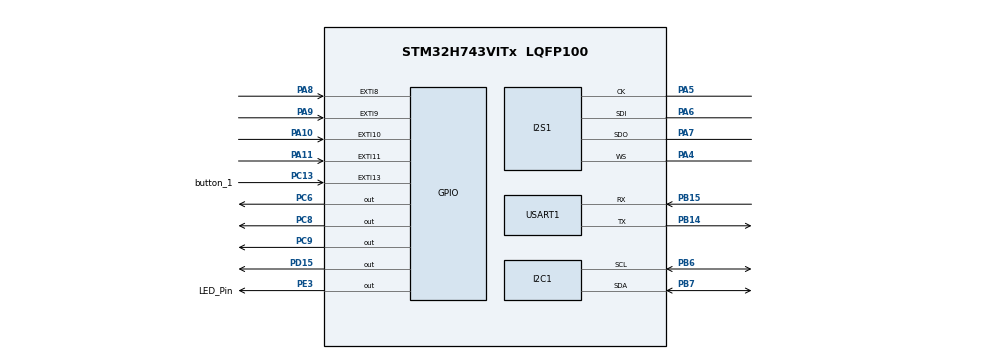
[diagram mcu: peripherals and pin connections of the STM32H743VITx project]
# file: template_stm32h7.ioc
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CORTEX_M7.CPU_DCache=Enabled
CORTEX_M7.CPU_ICache=Enabled
CORTEX_M7.default_mode_Activation=1
Dma.Request0=SPI1_RX
Dma.SPI1_RX.0.Direction=DMA_PERIPH_TO_MEMORY
Dma.SPI1_RX.0.EventEnable=DISABLE
Dma.SPI1_RX.0.FIFOMode=DMA_FIFOMODE_DISABLE
Dma.SPI1_RX.0.Instance=DMA1_Stream0
Dma.SPI1_RX.0.MemDataAlignment=DMA_MDATAALIGN_WORD
Dma.SPI1_RX.0.MemInc=DMA_MINC_ENABLE
Dma.SPI1_RX.0.Mode=DMA_CIRCULAR
Dma.SPI1_RX.0.PeriphDataAlignment=DMA_PDATAALIGN_WORD
Dma.SPI1_RX.0.PeriphInc=DMA_PINC_DISABLE
Dma.SPI1_RX.0.Polarity=HAL_DMAMUX_REQ_GEN_RISING
Dma.SPI1_RX.0.Priority=DMA_PRIORITY_LOW
Dma.SPI1_RX.0.RequestNumber=1
Dma.SPI1_RX.0.SignalID=NONE
Dma.SPI1_RX.0.SyncEnable=DISABLE
Dma.SPI1_RX.0.SyncPolarity=HAL_DMAMUX_SYNC_NO_EVENT
Dma.SPI1_RX.0.SyncRequestNumber=1
Dma.SPI1_RX.0.SyncSignalID=NONE
I2C1.Timing=0x307075B1
I2S1.AudioFreq=I2S_AUDIOFREQ_16K
I2S1.Data24BitAlignment=I2S_DATA_24BIT_ALIGNMENT_LEFT
I2S1.DataFormat=I2S_DATAFORMAT_24B
I2S1.ErrorAudioFreq=0.15 %
I2S1.Instance=SPI$Index
I2S1.RealAudioFreq=16.025 KHz
I2S1.WSInversion=I2S_WS_INVERSION_ENABLE
Mcu.Family=STM32H7
Mcu.Name=STM32H743VITx
Mcu.Package=LQFP100
NVIC.DMA1_Stream0_IRQn=true\:0\:0\:false\:false\:true\:false\:true\:true
NVIC.EXTI15_10_IRQn=true\:0\:0\:false\:false\:true\:true\:true\:true
NVIC.EXTI9_5_IRQn=true\:0\:0\:false\:false\:true\:true\:true\:true
NVIC.PriorityGroup=NVIC_PRIORITYGROUP_4
NVIC.TIM6_DAC_IRQn=true\:15\:0\:false\:false\:true\:false\:true\:true
NVIC.TimeBase=TIM6_DAC_IRQn
NVIC.TimeBaseIP=TIM6
PA10.GPIO_ModeDefaultEXTI=GPIO_MODE_IT_FALLING
PA10.GPIO_PuPd=GPIO_PULLUP
PA10.Signal=GPXTI10
PA11.GPIO_ModeDefaultEXTI=GPIO_MODE_IT_FALLING
PA11.GPIO_PuPd=GPIO_PULLUP
PA11.Signal=GPXTI11
PA13\ (JTMS/SWDIO).Mode=Serial_Wire
PA13\ (JTMS/SWDIO).Signal=DEBUG_JTMS-SWDIO
PA14\ (JTCK/SWCLK).Mode=Serial_Wire
PA14\ (JTCK/SWCLK).Signal=DEBUG_JTCK-SWCLK
PA4.GPIO_Speed=GPIO_SPEED_FREQ_VERY_HIGH
PA4.Mode=Full_Duplex_Master
PA4.Signal=I2S1_WS
PA5.GPIO_Speed=GPIO_SPEED_FREQ_VERY_HIGH
PA5.Mode=Full_Duplex_Master
PA5.Signal=I2S1_CK
PA6.GPIO_PuPd=GPIO_PULLDOWN
PA6.GPIO_Speed=GPIO_SPEED_FREQ_VERY_HIGH
PA6.Mode=Full_Duplex_Master
PA6.Signal=I2S1_SDI
PA7.Mode=Full_Duplex_Master
PA7.Signal=I2S1_SDO
PA8.GPIO_ModeDefaultEXTI=GPIO_MODE_IT_FALLING
PA8.GPIO_PuPd=GPIO_PULLUP
PA8.Signal=GPXTI8
PA9.GPIO_ModeDefaultEXTI=GPIO_MODE_IT_FALLING
PA9.GPIO_PuPd=GPIO_PULLUP
PA9.Signal=GPXTI9
PB14.Mode=Asynchronous
PB14.Signal=USART1_TX
PB15.Mode=Asynchronous
PB15.Signal=USART1_RX
PB6.Mode=I2C
PB6.Signal=I2C1_SCL
PB7.Mode=I2C
PB7.Signal=I2C1_SDA
PC13.GPIO_Label=button_1
PC13.GPIO_PuPd=GPIO_PULLDOWN
PC13.Signal=GPXTI13
PC14-OSC32_IN\ (OSC32_IN).Mode=LSE-External-Oscillator
PC14-OSC32_IN\ (OSC32_IN).Signal=RCC_OSC32_IN
PC15-OSC32_OUT\ (OSC32_OUT).Mode=LSE-External-Oscillator
PC15-OSC32_OUT\ (OSC32_OUT).Signal=RCC_OSC32_OUT
PC6.GPIO_Speed=GPIO_SPEED_FREQ_VERY_HIGH
PC6.Signal=GPIO_Output
PC8.GPIO_Speed=GPIO_SPEED_FREQ_VERY_HIGH
PC8.Signal=GPIO_Output
PC9.GPIO_Speed=GPIO_SPEED_FREQ_VERY_HIGH
PC9.Signal=GPIO_Output
PD15.GPIO_Speed=GPIO_SPEED_FREQ_VERY_HIGH
PD15.Signal=GPIO_Output
PE3.GPIO_Label=LED_Pin
PE3.GPIO_PuPd=GPIO_PULLUP
PE3.GPIO_Speed=GPIO_SPEED_FREQ_VERY_HIGH
PE3.Signal=GPIO_Output
PH0-OSC_IN\ (PH0).Mode=HSE-External-Oscillator
PH0-OSC_IN\ (PH0).Signal=RCC_OSC_IN
PH1-OSC_OUT\ (PH1).Mode=HSE-External-Oscillator
PH1-OSC_OUT\ (PH1).Signal=RCC_OSC_OUT
ProjectManager.HeapSize=0x800
ProjectManager.StackSize=0x800
ProjectManager.TargetToolchain=STM32CubeIDE
RCC.ADCFreq_Value=200000000
RCC.APB1CLKDivider=RCC_HCLK_DIV4
RCC.APB1Freq_Value=120000000
RCC.APB2CLKDivider=RCC_HCLK_DIV2
RCC.APB2Freq_Value=120000000
RCC.APB3Freq_Value=120000000
RCC.APB4Freq_Value=120000000
RCC.CortexFreq_Value=480000000
RCC.D1PPRE=RCC_APB3_DIV2
RCC.D2PPRE1=RCC_APB1_DIV2
RCC.D2PPRE2=RCC_APB2_DIV2
RCC.D3PPRE=RCC_APB4_DIV2
RCC.DIVM1=5
RCC.DIVM2=5
RCC.DIVM3=4
RCC.DIVN1=192
RCC.DIVN2=80
RCC.DIVN3=480
RCC.DIVQ1=20
RCC.DIVQ3=8
RCC.FLatency=FLASH_LATENCY_4
RCC.HCLKFreq_Value=240000000
RCC.HPRE=RCC_HCLK_DIV2
RCC.HSE_VALUE=25000000
RCC.PLL2FRACN=0
RCC.PLL3FRACN=0
RCC.PLLFRACN=0
RCC.PLLM=25
RCC.PLLMUL=RCC_PLL_MUL9
RCC.PLLN=432
RCC.PLLQ=9
RCC.PLLSourceVirtual=RCC_PLLSOURCE_HSE
RCC.PRESCALERUSB=RCC_USBCLKSOURCE_PLL_DIV1_5
RCC.PWR_Regulator_Voltage_Scale=PWR_REGULATOR_VOLTAGE_SCALE0
RCC.SPI123CLockSelection=RCC_SPI123CLKSOURCE_PLL2
RCC.SYSCLKFreq_VALUE=480000000
RCC.SYSCLKSource=RCC_SYSCLKSOURCE_PLLCLK
RCC.SYSCLKSourceVirtual=RCC_SYSCLKSOURCE_PLLCLK
RCC.USBFreq_Value=48000000
STMicroelectronics.X-CUBE-AI.10.0.0.ActivationBufferSizeList=143044
STMicroelectronics.X-CUBE-AI.10.0.0.ActivationBuffers=pool0
STMicroelectronics.X-CUBE-AI.10.0.0.ActivationNames=pool0
STMicroelectronics.X-CUBE-AI.10.0.0.ActivationSizes=AI_NETWORK_DATA_ACTIVATION_1_SIZE
STMicroelectronics.X-CUBE-AI.10.0.0.ApplicationCcDeviceJjApplication=Validation
STMicroelectronics.X-CUBE-AI.10.0.0.BSP.number=1
STMicroelectronics.X-CUBE-AI.10.0.0.HeapSize=0x800
STMicroelectronics.X-CUBE-AI.10.0.0.InternalRamActivationBufferMaxSize=AI_NETWORK_DATA_ACTIVATIONS_SIZE
STMicroelectronics.X-CUBE-AI.10.0.0.LatestDirectoryUsed-23a5d2a3259b84d5ab143782c94374b90ed32390b56418b2c5c6ee772b9fe1ea=C\:\\GitHub\\voiceprint_recognition\\models\\voiceprint_model
STMicroelectronics.X-CUBE-AI.10.0.0.MaximumNumberOfInputLayer=1
STMicroelectronics.X-CUBE-AI.10.0.0.MaximumNumberOfOutputLayer=1
STMicroelectronics.X-CUBE-AI.10.0.0.MaximumSizeOfInputLayer=1
STMicroelectronics.X-CUBE-AI.10.0.0.MaximumSizeOfOutputLayer=1
STMicroelectronics.X-CUBE-AI.10.0.0.ModelActualCompression-23a5d2a3259b84d5ab143782c94374b90ed32390b56418b2c5c6ee772b9fe1ea=0.0
STMicroelectronics.X-CUBE-AI.10.0.0.ModelCompression-23a5d2a3259b84d5ab143782c94374b90ed32390b56418b2c5c6ee772b9fe1ea=None
STMicroelectronics.X-CUBE-AI.10.0.0.ModelFlashOccupation-23a5d2a3259b84d5ab143782c94374b90ed32390b56418b2c5c6ee772b9fe1ea=298795
STMicroelectronics.X-CUBE-AI.10.0.0.ModelHashList=23a5d2a3259b84d5ab143782c94374b90ed32390b56418b2c5c6ee772b9fe1ea
STMicroelectronics.X-CUBE-AI.10.0.0.ModelKind-23a5d2a3259b84d5ab143782c94374b90ed32390b56418b2c5c6ee772b9fe1ea=TFLITE
STMicroelectronics.X-CUBE-AI.10.0.0.ModelMacc-23a5d2a3259b84d5ab143782c94374b90ed32390b56418b2c5c6ee772b9fe1ea=33718160
STMicroelectronics.X-CUBE-AI.10.0.0.ModelName-23a5d2a3259b84d5ab143782c94374b90ed32390b56418b2c5c6ee772b9fe1ea=network
STMicroelectronics.X-CUBE-AI.10.0.0.ModelNameList=network
STMicroelectronics.X-CUBE-AI.10.0.0.ModelRamOccupation-23a5d2a3259b84d5ab143782c94374b90ed32390b56418b2c5c6ee772b9fe1ea=143044
STMicroelectronics.X-CUBE-AI.10.0.0.ModelStructureFile-23a5d2a3259b84d5ab143782c94374b90ed32390b56418b2c5c6ee772b9fe1ea=C\:\\GitHub\\voiceprint_recognition\\models\\voiceprint_model\\voiceprint_model.tflite
STMicroelectronics.X-CUBE-AI.10.0.0.ModelType-23a5d2a3259b84d5ab143782c94374b90ed32390b56418b2c5c6ee772b9fe1ea=STM32Cube.AI MCU runtime
STMicroelectronics.X-CUBE-AI.10.0.0.ReadyForCodeGeneration=true
STMicroelectronics.X-CUBE-AI.10.0.0.StackSize=0x800
STMicroelectronics.X-CUBE-AI.10.0.0.WorkingBufferStartAddrList=0xFFFFFFFF
STMicroelectronics.X-CUBE-AI.10.0.0.XAaCUBEAaAICcArtificialOoIntelligenceJjCore=true
STMicroelectronics.X-CUBE-AI.10.0.0.copyWeightToRam=false
STMicroelectronics.X-CUBE-AI.10.0.0.copyWeightToRam-23a5d2a3259b84d5ab143782c94374b90ed32390b56418b2c5c6ee772b9fe1ea=false
STMicroelectronics.X-CUBE-AI.10.0.0.customLayerConfigEnabled=false
STMicroelectronics.X-CUBE-AI.10.0.0.customLayerConfigEnabled-23a5d2a3259b84d5ab143782c94374b90ed32390b56418b2c5c6ee772b9fe1ea=false
STMicroelectronics.X-CUBE-AI.10.0.0.noOnnxIoTranspose=false
STMicroelectronics.X-CUBE-AI.10.0.0.noOnnxIoTranspose-23a5d2a3259b84d5ab143782c94374b90ed32390b56418b2c5c6ee772b9fe1ea=false
STMicroelectronics.X-CUBE-AI.10.0.0.useInputAllocation=true
STMicroelectronics.X-CUBE-AI.10.0.0.useInputAllocation-23a5d2a3259b84d5ab143782c94374b90ed32390b56418b2c5c6ee772b9fe1ea=true
STMicroelectronics.X-CUBE-AI.10.0.0.useOutputAllocation=true
STMicroelectronics.X-CUBE-AI.10.0.0.useOutputAllocation-23a5d2a3259b84d5ab143782c94374b90ed32390b56418b2c5c6ee772b9fe1ea=true
STMicroelectronics.X-CUBE-AI.10.0.00.BSP.STBoard=false
STMicroelectronics.X-CUBE-AI.10.0.00.BSP.api=Unknown
STMicroelectronics.X-CUBE-AI.10.0.00.BSP.condition=\!SEMDeviceJjApplicationJjApplicationTemplate
STMicroelectronics.X-CUBE-AI.10.0.00.BSP.instance=USART1
STMicroelectronics.X-CUBE-AI.10.0.00.BSP.ip=USART
STMicroelectronics.X-CUBE-AI.10.0.00.BSP.mode=Asynchronous
STMicroelectronics.X-CUBE-AI.10.0.00.BSP.name=COM Port
STMicroelectronics.X-CUBE-AI.10.0.00.BSP.solution=USART1
STMicroelectronics.X-CUBE-ALGOBUILD.1.4.0.LibraryCcDSPOoLibraryJjDSPOoLibrary=true
USART1.VirtualMode-Asynchronous=VM_ASYNC
VP_MEMORYMAP_VS_MEMORYMAP.Mode=CurAppReg
VP_RTC_VS_RTC_Activate.Mode=RTC_Enabled
VP_STMicroelectronics.X-CUBE-AI_VS_ArtificialOoIntelligenceJjXAaCUBEAaAI_10.0.0.Mode=ArtificialOoIntelligenceJjXAaCUBEAaAI
VP_STMicroelectronics.X-CUBE-AI_VS_DeviceJjApplication_10.0.0.Mode=DeviceJjApplication
VP_STMicroelectronics.X-CUBE-ALGOBUILD_VS_DSPOoLibraryJjLibrary_1.4.0_1.4.0.Mode=DSPOoLibraryJjLibrary
VP_SYS_VS_tim6.Mode=TIM6
board=custom

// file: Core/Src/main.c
/* USER CODE BEGIN Header */
/**
  ******************************************************************************
  * @file           : main.c
  * @brief          : Main program body
  ******************************************************************************
  * @attention
  *
  * Copyright (c) 2025 STMicroelectronics.
  * All rights reserved.
  *
  * This software is licensed under terms that can be found in the LICENSE file
  * in the root directory of this software component.
  * If no LICENSE file comes with this software, it is provided AS-IS.
  *
  ******************************************************************************
  */
/* USER CODE END Header */
#include "main.h"
#include "dma.h"
#include "i2c.h"
#include "i2s.h"
#include "memorymap.h"
#include "rtc.h"
#include "usart.h"
#include "gpio.h"
#include "app_x-cube-ai.h"

/* USER CODE BEGIN Includes */
#include "audio_capture.h"
#include "audio_process.h"
#include "SEGGER_RTT.h"
#include "SEGGER_RTT_Conf.h"
/* USER CODE END Includes */

void SystemClock_Config(void);
static void MPU_Config(void);

int main(void)
{

  /* MPU Configuration--------------------------------------------------------*/
  MPU_Config();

  /* Enable the CPU Cache */

  /* Enable I-Cache---------------------------------------------------------*/
  SCB_EnableICache();

  /* Enable D-Cache---------------------------------------------------------*/
  SCB_EnableDCache();

  /* MCU Configuration--------------------------------------------------------*/

  /* Reset of all peripherals, Initializes the Flash interface and the Systick. */
  HAL_Init();

  /* Configure the system clock */
  SystemClock_Config();

  /* Initialize all configured peripherals */
  MX_GPIO_Init();
  MX_DMA_Init();
  MX_RTC_Init();
  MX_I2S1_Init();
  MX_I2C1_Init();
  MX_USART1_UART_Init();
  MX_X_CUBE_AI_Init();
  /* USER CODE BEGIN 2 */
  AudioCapture_Init();
  SEGGER_RTT_Init();
  SEGGER_RTT_printf(0, "Test\n");
  /* USER CODE END 2 */

  /* Infinite loop */
  /* USER CODE BEGIN WHILE */
  while (1)
  {
	  if(captureDoneFlag)
	  {
		  captureDoneFlag = 0;  // 清除标志

	       /* 处理音频数据 */
		  ProcessAudio(audioBuffer, AUDIO_BUFFER_SAMPLES);

	       /* 恢复空闲状态，等待下一次按键 */
	       audioState = AUDIO_STATE_IDLE;

	       SEGGER_RTT_printf(0, "Ready for next capture. Press button again.\r\n");
	     }
    /* USER CODE END WHILE */

  MX_X_CUBE_AI_Process();
  }
}

void SystemClock_Config(void)
{
  RCC_OscInitTypeDef RCC_OscInitStruct = {0};
  RCC_ClkInitTypeDef RCC_ClkInitStruct = {0};

  /** Supply configuration update enable
  */
  HAL_PWREx_ConfigSupply(PWR_LDO_SUPPLY);

  /** Configure the main internal regulator output voltage
  */
  __HAL_PWR_VOLTAGESCALING_CONFIG(PWR_REGULATOR_VOLTAGE_SCALE0);

  while(!__HAL_PWR_GET_FLAG(PWR_FLAG_VOSRDY)) {}

  /** Initializes the RCC Oscillators according to the specified parameters
  * in the RCC_OscInitTypeDef structure.
  */
  RCC_OscInitStruct.OscillatorType = RCC_OSCILLATORTYPE_LSI|RCC_OSCILLATORTYPE_HSE;
  RCC_OscInitStruct.HSEState = RCC_HSE_ON;
  RCC_OscInitStruct.LSIState = RCC_LSI_ON;
  RCC_OscInitStruct.PLL.PLLState = RCC_PLL_ON;
  RCC_OscInitStruct.PLL.PLLSource = RCC_PLLSOURCE_HSE;
  RCC_OscInitStruct.PLL.PLLM = 5;
  RCC_OscInitStruct.PLL.PLLN = 192;
  RCC_OscInitStruct.PLL.PLLP = 2;
  RCC_OscInitStruct.PLL.PLLQ = 20;
  RCC_OscInitStruct.PLL.PLLR = 2;
  RCC_OscInitStruct.PLL.PLLRGE = RCC_PLL1VCIRANGE_2;
  RCC_OscInitStruct.PLL.PLLVCOSEL = RCC_PLL1VCOWIDE;
  RCC_OscInitStruct.PLL.PLLFRACN = 0;
  if (HAL_RCC_OscConfig(&RCC_OscInitStruct) != HAL_OK)
  {
    Error_Handler();
  }

  /** Initializes the CPU, AHB and APB buses clocks
  */
  RCC_ClkInitStruct.ClockType = RCC_CLOCKTYPE_HCLK|RCC_CLOCKTYPE_SYSCLK
                              |RCC_CLOCKTYPE_PCLK1|RCC_CLOCKTYPE_PCLK2
                              |RCC_CLOCKTYPE_D3PCLK1|RCC_CLOCKTYPE_D1PCLK1;
  RCC_ClkInitStruct.SYSCLKSource = RCC_SYSCLKSOURCE_PLLCLK;
  RCC_ClkInitStruct.SYSCLKDivider = RCC_SYSCLK_DIV1;
  RCC_ClkInitStruct.AHBCLKDivider = RCC_HCLK_DIV2;
  RCC_ClkInitStruct.APB3CLKDivider = RCC_APB3_DIV2;
  RCC_ClkInitStruct.APB1CLKDivider = RCC_APB1_DIV2;
  RCC_ClkInitStruct.APB2CLKDivider = RCC_APB2_DIV2;
  RCC_ClkInitStruct.APB4CLKDivider = RCC_APB4_DIV2;

  if (HAL_RCC_ClockConfig(&RCC_ClkInitStruct, FLASH_LATENCY_4) != HAL_OK)
  {
    Error_Handler();
  }
}

 /* MPU Configuration */

void MPU_Config(void)
{
  MPU_Region_InitTypeDef MPU_InitStruct = {0};

  /* Disables the MPU */
  HAL_MPU_Disable();

  /** Initializes and configures the Region and the memory to be protected
  */
  MPU_InitStruct.Enable = MPU_REGION_ENABLE;
  MPU_InitStruct.Number = MPU_REGION_NUMBER0;
  MPU_InitStruct.BaseAddress = 0x0;
  MPU_InitStruct.Size = MPU_REGION_SIZE_4GB;
  MPU_InitStruct.SubRegionDisable = 0x87;
  MPU_InitStruct.TypeExtField = MPU_TEX_LEVEL0;
  MPU_InitStruct.AccessPermission = MPU_REGION_NO_ACCESS;
  MPU_InitStruct.DisableExec = MPU_INSTRUCTION_ACCESS_DISABLE;
  MPU_InitStruct.IsShareable = MPU_ACCESS_SHAREABLE;
  MPU_InitStruct.IsCacheable = MPU_ACCESS_NOT_CACHEABLE;
  MPU_InitStruct.IsBufferable = MPU_ACCESS_NOT_BUFFERABLE;

  HAL_MPU_ConfigRegion(&MPU_InitStruct);
  /* Enables the MPU */
  HAL_MPU_Enable(MPU_PRIVILEGED_DEFAULT);

}

void HAL_TIM_PeriodElapsedCallback(TIM_HandleTypeDef *htim)
{
  if (htim->Instance == TIM6)
  {
    HAL_IncTick();
  }
}

void Error_Handler(void)
{
  __disable_irq();
  while (1)
  {
  }
}
